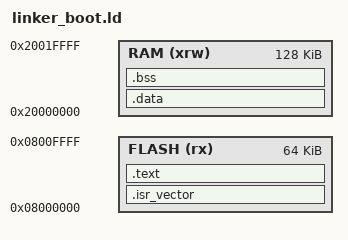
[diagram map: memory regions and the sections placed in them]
/* linker_boot.ld */

ENTRY(Reset_Handler)

MEMORY
{
  FLASH (rx) : ORIGIN = 0x08000000, LENGTH = 64K   /* bootloader */
  RAM   (xrw): ORIGIN = 0x20000000, LENGTH = 128K
}

_estack = ORIGIN(RAM) + LENGTH(RAM); /* stack top */

/* Sections */
SECTIONS
{
  .isr_vector :
  {
    KEEP(*(.isr_vector))
  } > FLASH

  .text :
  {
    *(.text*)
    *(.rodata*)
    _etext = .;
  } > FLASH

  .data : AT (ADDR(.text) + SIZEOF(.text))
  {
    _sdata = .;
    *(.data*)
    _edata = .;
  } > RAM
  _sidata = LOADADDR(.data);

  .bss :
  {
    _sbss = .;
    *(.bss*)
    *(COMMON)
    _ebss = .;
  } > RAM
}
